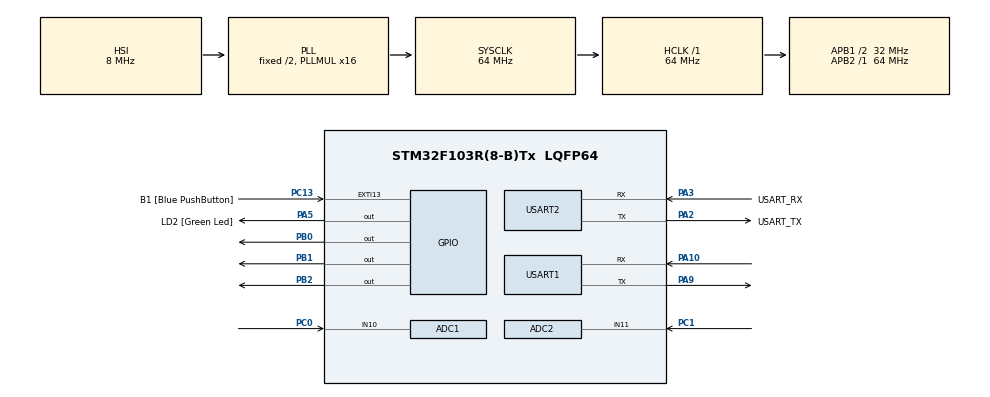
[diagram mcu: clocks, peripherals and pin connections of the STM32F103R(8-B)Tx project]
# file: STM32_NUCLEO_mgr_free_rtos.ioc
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Mcu.Family=STM32F1
PA2.GPIO_PuPd=GPIO_NOPULL
ADC2.Channel-0\#ChannelRegularConversion=ADC_CHANNEL_11
PA14.GPIO_Label=TCK
PA3.GPIO_PuPd=GPIO_NOPULL
PA2.GPIO_Speed=GPIO_SPEED_FREQ_LOW
PA3.GPIO_Speed=GPIO_SPEED_FREQ_LOW
RCC.SYSCLKSource=RCC_SYSCLKSOURCE_PLLCLK
ProjectManager.StackSize=0x400
VP_FREERTOS_VS_CMSIS_V2.Mode=CMSIS_V2
PD1-OSC_OUT.Signal=RCC_OSC_OUT
RCC.HCLKFreq_Value=64000000
RCC.APB2TimFreq_Value=64000000
RCC.AHBFreq_Value=64000000
NVIC.EXTI15_10_IRQn=true\:5\:0\:false\:false\:true\:true\:true\:true
ADC1.Channel-0\#ChannelRegularConversion=ADC_CHANNEL_10
PB2.Signal=GPIO_Output
RCC.RTCClockSelection=RCC_RTCCLKSOURCE_LSE
RCC.PLLMUL=RCC_PLL_MUL16
PC14-OSC32_IN.Mode=LSE-External-Oscillator
PA14.Mode=Serial_Wire
PA5.GPIO_PuPd=GPIO_NOPULL
ADC1.SamplingTime-0\#ChannelRegularConversion=ADC_SAMPLETIME_1CYCLE_5
Mcu.Package=LQFP64
PB1.Signal=GPIO_Output
NVIC.TimeBase=TIM4_IRQn
USART2.VirtualMode=VM_ASYNC
PC13-TAMPER-RTC.GPIO_PuPd=GPIO_NOPULL
PA2.GPIO_Label=USART_TX
NVIC.TimeBaseIP=TIM4
PA10.Signal=USART1_RX
ADC2.SamplingTime-0\#ChannelRegularConversion=ADC_SAMPLETIME_1CYCLE_5
RCC.APB1TimFreq_Value=64000000
ADC2.Rank-0\#ChannelRegularConversion=1
NVIC.USART1_IRQn=true\:5\:0\:false\:false\:true\:true\:true\:true
PA3.Signal=USART2_RX
PA2.GPIO_Mode=GPIO_MODE_AF_PP
PB3.GPIO_Label=SWO
PC15-OSC32_OUT.Mode=LSE-External-Oscillator
FREERTOS.Tasks01=USART_Task,24,128,USART_Process,Default,NULL,Dynamic,NULL,NULL;GPIO_Task,8,128,GPIO_Process,Default,NULL,Dynamic,NULL,NULL
ADC1.Rank-0\#ChannelRegularConversion=1
PD1-OSC_OUT.Mode=HSE-External-Clock-Source
PA10.Mode=Asynchronous
PC13-TAMPER-RTC.Signal=GPXTI13
PD0-OSC_IN.Signal=RCC_OSC_IN
PC0.Signal=ADCx_IN10
RCC.APB1CLKDivider=RCC_HCLK_DIV2
PC14-OSC32_IN.Signal=RCC_OSC32_IN
PA13.Signal=SYS_JTMS-SWDIO
PA3.Mode=Asynchronous
PA9.Mode=Asynchronous
ProjectManager.TargetToolchain=STM32CubeIDE
PA3.GPIO_Mode=GPIO_MODE_AF_PP
PA9.Signal=USART1_TX
RCC.USBFreq_Value=64000000
PC15-OSC32_OUT.Signal=RCC_OSC32_OUT
PD0-OSC_IN.Mode=HSE-External-Clock-Source
PA5.Signal=GPIO_Output
board=NUCLEO-F103RB
PC13-TAMPER-RTC.GPIO_Label=B1 [Blue PushButton]
RCC.APB2Freq_Value=64000000
SH.ADCx_IN11.0=ADC2_IN11,IN11
PA5.GPIO_ModeDefaultOutputPP=GPIO_MODE_OUTPUT_PP
PA13.Mode=Serial_Wire
Mcu.Name=STM32F103R(8-B)Tx
PA13.GPIO_Label=TMS
PA2.Signal=USART2_TX
PB3.Signal=SYS_JTDO-TRACESWO
RCC.SYSCLKFreq_VALUE=64000000
ADC1.master=1
PA5.GPIO_Label=LD2 [Green Led]
ADC2.NbrOfConversionFlag=1
USART1.VirtualMode=VM_ASYNC
PA14.Signal=SYS_JTCK-SWCLK
SH.ADCx_IN10.0=ADC1_IN10,IN10
ProjectManager.HeapSize=0x200
VP_SYS_VS_tim4.Mode=TIM4
PA5.GPIO_Speed=GPIO_SPEED_FREQ_LOW
NVIC.PriorityGroup=NVIC_PRIORITYGROUP_4
ADC1.NbrOfConversionFlag=1
PA2.Mode=Asynchronous
NVIC.TIM4_IRQn=true\:0\:0\:false\:false\:true\:false\:false\:true
RCC.APB1Freq_Value=32000000
PB0.Signal=GPIO_Output
PC1.Signal=ADCx_IN11
PA3.GPIO_Label=USART_RX

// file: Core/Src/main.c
/* USER CODE BEGIN Header */
/**
  ******************************************************************************
  * @file           : main.c
  * @brief          : Main program body
  ******************************************************************************
  * @attention
  *
  * <h2><center>&copy; Copyright (c) 2021 STMicroelectronics.
  * All rights reserved.</center></h2>
  *
  * This software component is licensed by ST under BSD 3-Clause license,
  * the "License"; You may not use this file except in compliance with the
  * License. You may obtain a copy of the License at:
  *                        opensource.org/licenses/BSD-3-Clause
  *
  ******************************************************************************
  */
/* USER CODE END Header */
#include "main.h"
#include "cmsis_os.h"
#include "task.h"
#include "ring_buffer.h"
#include "string.h"
#include "stdio.h"

ADC_HandleTypeDef hadc1;
ADC_HandleTypeDef hadc2;

UART_HandleTypeDef huart1;
UART_HandleTypeDef huart2;

static char RingBufferData_Rx[1024];
static char RingBufferData_Tx[1024];
/* Definitions for USART_Task */
osThreadId_t USART_TaskHandle;
const osThreadAttr_t USART_Task_attributes = {
  .name = "USART_Task",
  .stack_size = 128 * 4,
  .priority = (osPriority_t) osPriorityNormal,
};
/* Definitions for GPIO_Task */
osThreadId_t GPIO_TaskHandle;
const osThreadAttr_t GPIO_Task_attributes = {
  .name = "GPIO_Task",
  .stack_size = 128 * 4,
  .priority = (osPriority_t) osPriorityLow,
};

void SystemClock_Config(void);
static void MX_GPIO_Init(void);
static void MX_USART2_UART_Init(void);
static void MX_USART1_UART_Init(void);
static void MX_ADC1_Init(void);
static void MX_ADC2_Init(void);
void USART_Process(void *argument);
void GPIO_Process(void *argument);
void USART_POLL_WriteString(const char *string);

int main(void)
{

  /* MCU Configuration--------------------------------------------------------*/

  /* Reset of all peripherals, Initializes the Flash interface and the Systick. */
  HAL_Init();

  /* Configure the system clock */
  SystemClock_Config();

  /* Initialize all configured peripherals */
  MX_GPIO_Init();
  MX_USART2_UART_Init();
  MX_USART1_UART_Init();
  MX_ADC1_Init();
  MX_ADC2_Init();

  /* Init scheduler */
  osKernelInitialize();

  /* Create the thread(s) */
  /* creation of USART_Task */
  USART_TaskHandle = osThreadNew(USART_Process, NULL, &USART_Task_attributes);

  /* creation of GPIO_Task */
  GPIO_TaskHandle = osThreadNew(GPIO_Process, NULL, &GPIO_Task_attributes);

  /* Start scheduler */
  osKernelStart();

  /* We should never get here as control is now taken by the scheduler */
  /* Infinite loop */
  while (1)
  {

  }
}

void SystemClock_Config(void)
{
  RCC_OscInitTypeDef RCC_OscInitStruct = {0};
  RCC_ClkInitTypeDef RCC_ClkInitStruct = {0};
  RCC_PeriphCLKInitTypeDef PeriphClkInit = {0};

  /** Initializes the RCC Oscillators according to the specified parameters
  * in the RCC_OscInitTypeDef structure.
  */
  RCC_OscInitStruct.OscillatorType = RCC_OSCILLATORTYPE_HSI;
  RCC_OscInitStruct.HSIState = RCC_HSI_ON;
  RCC_OscInitStruct.HSICalibrationValue = RCC_HSICALIBRATION_DEFAULT;
  RCC_OscInitStruct.PLL.PLLState = RCC_PLL_ON;
  RCC_OscInitStruct.PLL.PLLSource = RCC_PLLSOURCE_HSI_DIV2;
  RCC_OscInitStruct.PLL.PLLMUL = RCC_PLL_MUL16;
  if (HAL_RCC_OscConfig(&RCC_OscInitStruct) != HAL_OK)
  {
    Error_Handler();
  }
  /** Initializes the CPU, AHB and APB buses clocks
  */
  RCC_ClkInitStruct.ClockType = RCC_CLOCKTYPE_HCLK|RCC_CLOCKTYPE_SYSCLK
                              |RCC_CLOCKTYPE_PCLK1|RCC_CLOCKTYPE_PCLK2;
  RCC_ClkInitStruct.SYSCLKSource = RCC_SYSCLKSOURCE_PLLCLK;
  RCC_ClkInitStruct.AHBCLKDivider = RCC_SYSCLK_DIV1;
  RCC_ClkInitStruct.APB1CLKDivider = RCC_HCLK_DIV2;
  RCC_ClkInitStruct.APB2CLKDivider = RCC_HCLK_DIV1;

  if (HAL_RCC_ClockConfig(&RCC_ClkInitStruct, FLASH_LATENCY_2) != HAL_OK)
  {
    Error_Handler();
  }
  PeriphClkInit.PeriphClockSelection = RCC_PERIPHCLK_ADC;
  PeriphClkInit.AdcClockSelection = RCC_ADCPCLK2_DIV2;
  if (HAL_RCCEx_PeriphCLKConfig(&PeriphClkInit) != HAL_OK)
  {
    Error_Handler();
  }
}

static void MX_ADC1_Init(void)
{

  ADC_ChannelConfTypeDef sConfig = {0};

  /** Common config
  */
  hadc1.Instance = ADC1;
  hadc1.Init.ScanConvMode = ADC_SCAN_DISABLE;
  hadc1.Init.ContinuousConvMode = DISABLE;
  hadc1.Init.DiscontinuousConvMode = DISABLE;
  hadc1.Init.ExternalTrigConv = ADC_SOFTWARE_START;
  hadc1.Init.DataAlign = ADC_DATAALIGN_RIGHT;
  hadc1.Init.NbrOfConversion = 1;
  if (HAL_ADC_Init(&hadc1) != HAL_OK)
  {
    Error_Handler();
  }
  /** Configure Regular Channel
  */
  sConfig.Channel = ADC_CHANNEL_10;
  sConfig.Rank = ADC_REGULAR_RANK_1;
  sConfig.SamplingTime = ADC_SAMPLETIME_1CYCLE_5;
  if (HAL_ADC_ConfigChannel(&hadc1, &sConfig) != HAL_OK)
  {
    Error_Handler();
  }

}

static void MX_ADC2_Init(void)
{

  ADC_ChannelConfTypeDef sConfig = {0};

  /** Common config
  */
  hadc2.Instance = ADC2;
  hadc2.Init.ScanConvMode = ADC_SCAN_DISABLE;
  hadc2.Init.ContinuousConvMode = DISABLE;
  hadc2.Init.DiscontinuousConvMode = DISABLE;
  hadc2.Init.ExternalTrigConv = ADC_SOFTWARE_START;
  hadc2.Init.DataAlign = ADC_DATAALIGN_RIGHT;
  hadc2.Init.NbrOfConversion = 1;
  if (HAL_ADC_Init(&hadc2) != HAL_OK)
  {
    Error_Handler();
  }
  /** Configure Regular Channel
  */
  sConfig.Channel = ADC_CHANNEL_11;
  sConfig.Rank = ADC_REGULAR_RANK_1;
  sConfig.SamplingTime = ADC_SAMPLETIME_1CYCLE_5;
  if (HAL_ADC_ConfigChannel(&hadc2, &sConfig) != HAL_OK)
  {
    Error_Handler();
  }

}

static void MX_USART1_UART_Init(void)
{
  GPIO_InitTypeDef gpio;
  gpio.Mode = GPIO_MODE_AF_PP;
  gpio.Pin = GPIO_PIN_9;
  gpio.Pull = GPIO_NOPULL;
  gpio.Speed = GPIO_SPEED_FREQ_LOW;
  HAL_GPIO_Init(GPIOA, &gpio);

  gpio.Mode = GPIO_MODE_AF_INPUT;
  gpio.Pin = GPIO_PIN_10;
  HAL_GPIO_Init(GPIOA, &gpio);

  huart1.Instance = USART1;
  huart1.Init.BaudRate = 9600;
  huart1.Init.WordLength = UART_WORDLENGTH_8B;
  huart1.Init.StopBits = UART_STOPBITS_1;
  huart1.Init.Parity = UART_PARITY_NONE;
  huart1.Init.Mode = UART_MODE_TX_RX;
  huart1.Init.HwFlowCtl = UART_HWCONTROL_NONE;
  huart1.Init.OverSampling = UART_OVERSAMPLING_16;
  if (HAL_UART_Init(&huart1) != HAL_OK)
  {
    Error_Handler();
  }

}

static void MX_USART2_UART_Init(void)
{

  huart2.Instance = USART2;
  huart2.Init.BaudRate = 115200;
  huart2.Init.WordLength = UART_WORDLENGTH_8B;
  huart2.Init.StopBits = UART_STOPBITS_1;
  huart2.Init.Parity = UART_PARITY_NONE;
  huart2.Init.Mode = UART_MODE_TX_RX;
  huart2.Init.HwFlowCtl = UART_HWCONTROL_NONE;
  huart2.Init.OverSampling = UART_OVERSAMPLING_16;
  if (HAL_UART_Init(&huart2) != HAL_OK)
  {
    Error_Handler();
  }

}

static void USART_Process_Data(const char *data)
{
  if(strncmp(data, "left", 4) == 0)
  {
    HAL_GPIO_WritePin(GPIOB,GPIO_PIN_1, GPIO_PIN_SET);
    HAL_GPIO_WritePin(GPIOB, GPIO_PIN_0, GPIO_PIN_SET);
    vTaskDelay(1);
    HAL_GPIO_WritePin(GPIOB, GPIO_PIN_0, GPIO_PIN_RESET);
  }
  if(strncmp(data, "righ", 4) == 0)
  {
    HAL_GPIO_WritePin(GPIOB,GPIO_PIN_1, GPIO_PIN_RESET);
    HAL_GPIO_WritePin(GPIOB, GPIO_PIN_0, GPIO_PIN_SET);
    vTaskDelay(1);
    HAL_GPIO_WritePin(GPIOB, GPIO_PIN_0, GPIO_PIN_RESET);
  }
  if(strncmp(data, "meas", 4) == 0)
  {
    HAL_ADC_Start(&hadc1);
    HAL_ADC_PollForConversion(&hadc1, HAL_MAX_DELAY);
    sprintf(RingBufferData_Tx, "Measure: %lx", HAL_ADC_GetValue(&hadc1));
    HAL_UART_Transmit(&huart1, (uint8_t *) RingBufferData_Tx, 22, HAL_MAX_DELAY);
  }
  if(strncmp(data, "te_1", 4) == 0)
  {
    for (int i=0; i < 100; i++)
    {
      HAL_GPIO_WritePin(GPIOB,GPIO_PIN_1, GPIO_PIN_SET);
      HAL_GPIO_WritePin(GPIOB, GPIO_PIN_0, GPIO_PIN_SET);
      vTaskDelay(1);
      HAL_GPIO_WritePin(GPIOB, GPIO_PIN_0, GPIO_PIN_RESET);
      HAL_UART_Transmit(&huart1, (uint8_t *) "current: x, voltage: y", 22, 1000);
      vTaskDelay(100);
    }
  }
}

void USART_POLL_WriteString(const char *s)
{
       HAL_UART_Transmit(&huart1, (uint8_t*)s, 1, 100);
}

static void MX_GPIO_Init(void)
{
  GPIO_InitTypeDef GPIO_InitStruct = {0};

  /* GPIO Ports Clock Enable */
  __HAL_RCC_GPIOC_CLK_ENABLE();
  __HAL_RCC_GPIOD_CLK_ENABLE();
  __HAL_RCC_GPIOA_CLK_ENABLE();
  __HAL_RCC_GPIOB_CLK_ENABLE();

  /*Configure GPIO pin Output Level */
  HAL_GPIO_WritePin(LD2_GPIO_Port, LD2_Pin, GPIO_PIN_RESET);

  /*Configure GPIO pin Output Level */
  HAL_GPIO_WritePin(GPIOB, GPIO_PIN_0|GPIO_PIN_1|GPIO_PIN_2, GPIO_PIN_RESET);

  /*Configure GPIO pin : B1_Pin */
  GPIO_InitStruct.Pin = B1_Pin;
  GPIO_InitStruct.Mode = GPIO_MODE_IT_RISING;
  GPIO_InitStruct.Pull = GPIO_NOPULL;
  HAL_GPIO_Init(B1_GPIO_Port, &GPIO_InitStruct);

  /*Configure GPIO pin : LD2_Pin */
  GPIO_InitStruct.Pin = LD2_Pin;
  GPIO_InitStruct.Mode = GPIO_MODE_OUTPUT_PP;
  GPIO_InitStruct.Pull = GPIO_NOPULL;
  GPIO_InitStruct.Speed = GPIO_SPEED_FREQ_LOW;
  HAL_GPIO_Init(LD2_GPIO_Port, &GPIO_InitStruct);

  /*Configure GPIO pins : PB0 PB1 PB2 */
  GPIO_InitStruct.Pin = GPIO_PIN_0|GPIO_PIN_1|GPIO_PIN_2;
  GPIO_InitStruct.Mode = GPIO_MODE_OUTPUT_PP;
  GPIO_InitStruct.Pull = GPIO_NOPULL;
  GPIO_InitStruct.Speed = GPIO_SPEED_FREQ_LOW;
  HAL_GPIO_Init(GPIOB, &GPIO_InitStruct);

  /* EXTI interrupt init*/
  HAL_NVIC_SetPriority(EXTI15_10_IRQn, 5, 0);
  HAL_NVIC_EnableIRQ(EXTI15_10_IRQn);

}

void USART_Process(void *argument)
{
  /* USER CODE BEGIN 5 */
  /* Infinite loop */
  for(;;)
  {
    if( HAL_UART_Receive(&huart1, (uint8_t *) RingBufferData_Rx, 4, 100) == HAL_OK)
    {
      USART_Process_Data(RingBufferData_Rx);
    }
  }
  /* USER CODE END 5 */
}

void GPIO_Process(void *argument)
{
  /* USER CODE BEGIN GPIO_Process */
  /* Infinite loop */
  for(;;)
  {
/*		    for (int i=0; i < 100; i++)
		    {
		      HAL_GPIO_WritePin(GPIOB, GPIO_PIN_0, GPIO_PIN_SET);
		      vTaskDelay(1);
		      HAL_GPIO_WritePin(GPIOB, GPIO_PIN_0, GPIO_PIN_RESET);
		      HAL_UART_Transmit(&huart1, (uint8_t *) "current: x, voltage: y", 22, 1000);
		      vTaskDelay(20);
		    }
		    vTaskDelay(8000);*/

  }
  /* USER CODE END GPIO_Process */
}

 /**
  * @brief  Period elapsed callback in non blocking mode
  * @note   This function is called  when TIM4 interrupt took place, inside
  * HAL_TIM_IRQHandler(). It makes a direct call to HAL_IncTick() to increment
  * a global variable "uwTick" used as application time base.
  * @param  htim : TIM handle
  * @retval None
  */
void HAL_TIM_PeriodElapsedCallback(TIM_HandleTypeDef *htim)
{
  if (htim->Instance == TIM4) {
    HAL_IncTick();
  }
}

void Error_Handler(void)
{
  __disable_irq();
  while (1)
  {
  }
}

/************************ (C) COPYRIGHT STMicroelectronics *****END OF FILE****/
